# AT32F407 register map
Vendor: Keil; Series: AT32F407; File version: 1.0
CPU: CM4 r0p1, little endian, no MPU, FPU, 4 interrupt priority bits
Registers are 32-bit, read-write, reset 0x0 unless marked. A register's access mark holds for its fields unless they carry their own. Offsets are from the block's base; [hi:lo] are bit positions; 'fields as' and 'values as' point back to an identical list.

## CRC — CRC calculation unit
Base 0x40023000
0x00 DT reset 0xFFFFFFFF — Data register
0x04 CDT — Common data register
  [7:0] CDT — Common Data
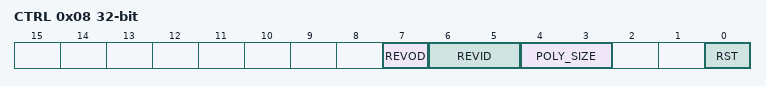
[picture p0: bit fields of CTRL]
0x08 CTRL — Control register
  [7] REVOD ro — Reverse output data
    0=NoEffect; 1=WordReverse
  [6:5] REVID — Reverse input data
    0=NoEffect; 1=ByteReverse; 2=HalfWordReverse; 3=WordReverse
  [4:3] POLY_SIZE — Polynomial size
    0=bits32 (32 bits); 1=bits16 (16 bits); 2=bits8 (8 bits); 3=bits7 (7 bits)
  [0] RST write-1-sets — Reset bit
    on write: 1=Reset CRC calculation unit, the data register is set as 0xFFFF FFFF
0x10 IDT reset 0xFFFFFFFF — Initial data register
0x14 POLY reset 0x4C11DB7 — Polynomial coefficient register

## FLASH — Flash memory controler
Base 0x40022000
0x00 PSR reset 0x30 — Performance selection register
0x04 UNLOCK wo
  [31:0] UKVAL — Unlock key value
0x08 USD_UNLOCK wo
  [31:0] USD_UKVAL — User system data Unlock key value
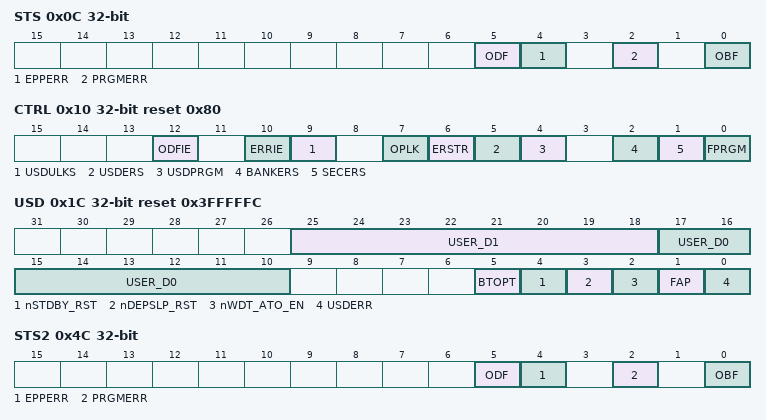
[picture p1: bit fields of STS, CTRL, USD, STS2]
0x0C STS — Status register
  [5] ODF — Operate done flag
  [4] EPPERR — Erase/program protection error
  [2] PRGMERR — program error
  [0] OBF ro — Operate busy flag
0x10 CTRL reset 0x80 — Control register
  [12] ODFIE — Operation done flag interrupt enable
  [10] ERRIE — Error interrupt enable
  [9] USDULKS — User system data unlock success
  [7] OPLK — Operation lock
  [6] ERSTR — Erasing start
  [5] USDERS — User system data erase
  [4] USDPRGM — User system data program
  [2] BANKERS — Bank erase
  [1] SECERS — Sector erase
  [0] FPRGM — Flash program
0x14 ADDR wo — Address register
  [31:0] FA — Flash Address
0x1C USD ro reset 0x3FFFFFC — User system data register
  [25:18] USER_D1 — User data 1
  [17:10] USER_D0 — User data 0
  [5] BTOPT — boot option
  [4] nSTDBY_RST — Standby reset
  [3] nDEPSLP_RST — Deepsleep reset
  [2] nWDT_ATO_EN — WDT auto enable
  [1] FAP — FLASH access protection
  [0] USDERR — User system data error
0x20 EPPS ro reset 0xFFFFFFFF — Erase/program protection status register
  [31:0] EPPS — Erase/program protection status
0x44 UNLOCK2 wo
  [31:0] UKVAL — Unlock key value
0x4C STS2 — Status 2 register
  fields as STS
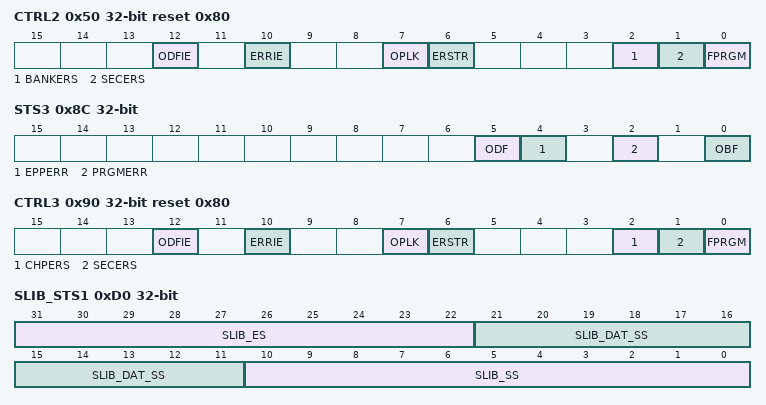
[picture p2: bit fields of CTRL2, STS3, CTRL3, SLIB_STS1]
0x50 CTRL2 reset 0x80 — Control 2 register
  [12] ODFIE — Operation done flag interrupt enable
  [10] ERRIE — Error interrupt enable
  [7] OPLK — Operation lock
  [6] ERSTR — Erasing start
  [2] BANKERS — Bank erase
  [1] SECERS — Sector erase
  [0] FPRGM — Flash program
0x54 ADDR2 wo — Address 2 register
  [31:0] FA — Flash Address
0x84 UNLOCK3 wo
  [31:0] UKVAL — Unlock key value
0x88 SELECT wo
  [31:0] SELECT — spim type selection
0x8C STS3 — Status 3 register
  fields as STS
0x90 CTRL3 reset 0x80 — Control 3 register
  [12] ODFIE — Operation done flag interrupt enable
  [10] ERRIE — Error interrupt enable
  [7] OPLK — Operation lock
  [6] ERSTR — Erasing start
  [2] CHPERS — Chip erase
  [1] SECERS — Sector erase
  [0] FPRGM — Flash program
0x94 ADDR3 wo — Address 3 register
  [31:0] FA — Flash Address
0x98 DA wo — Spim decryption address
  [31:0] FDA — Flash decryption address
0xCC SLIB_STS0 — sLib status 0 register
  [3] SLIB_ENF ro — sLib enabled flag
0xD0 SLIB_STS1 — sLib status 1 register
  [31:22] SLIB_ES ro — sLib end sector
  [21:11] SLIB_DAT_SS ro — sLib data start sector
  [10:0] SLIB_SS ro — sLib start sector
0xD4 SLIB_PWD_CLR wo — SLIB password clear register
  [31:0] SLIB_PCLR_VAL — sLib password clear value
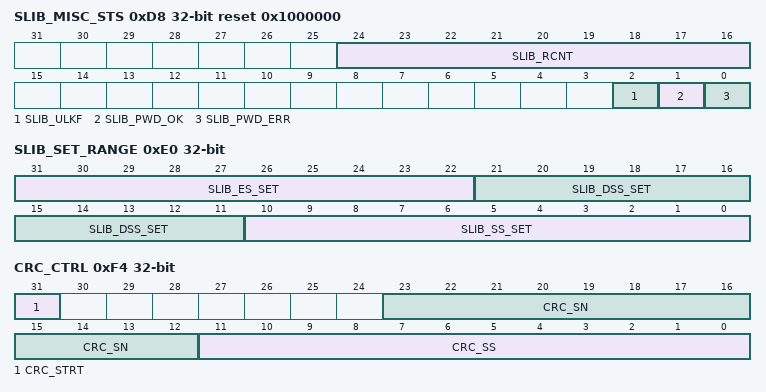
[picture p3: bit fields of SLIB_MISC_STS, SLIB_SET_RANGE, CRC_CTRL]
0xD8 SLIB_MISC_STS reset 0x1000000 — sLib misc status register
  [24:16] SLIB_RCNT ro — sLib remaining count
  [2] SLIB_ULKF ro — sLib unlock flag
  [1] SLIB_PWD_OK ro — sLib password ok
  [0] SLIB_PWD_ERR ro — sLib password error
0xDC SLIB_SET_PWD wo — sLib password setting register
  [31:0] SLIB_PSET_VAL — sLib password setting val
0xE0 SLIB_SET_RANGE wo — Configure sLib range register
  [31:22] SLIB_ES_SET — sLib end sector setting,valid input: 0~511
  [21:11] SLIB_DSS_SET — sLib data start sector setting,valid input: 0~511, 0 means no data area
  [10:0] SLIB_SS_SET — sLib start sector setting,valid input: 0~511
0xF0 SLIB_UNLOCK wo
  [31:0] SLIB_UKVAL — sLib unlock key value
0xF4 CRC_CTRL wo — CRC controler register
  [31] CRC_STRT — CRC start
  [23:12] CRC_SN — CRC sector numbler
  [11:0] CRC_SS — CRC start sector
0xF8 CRC_CHKR ro — CRC check result register
  [31:0] CRC_CHKR — CRC check result
